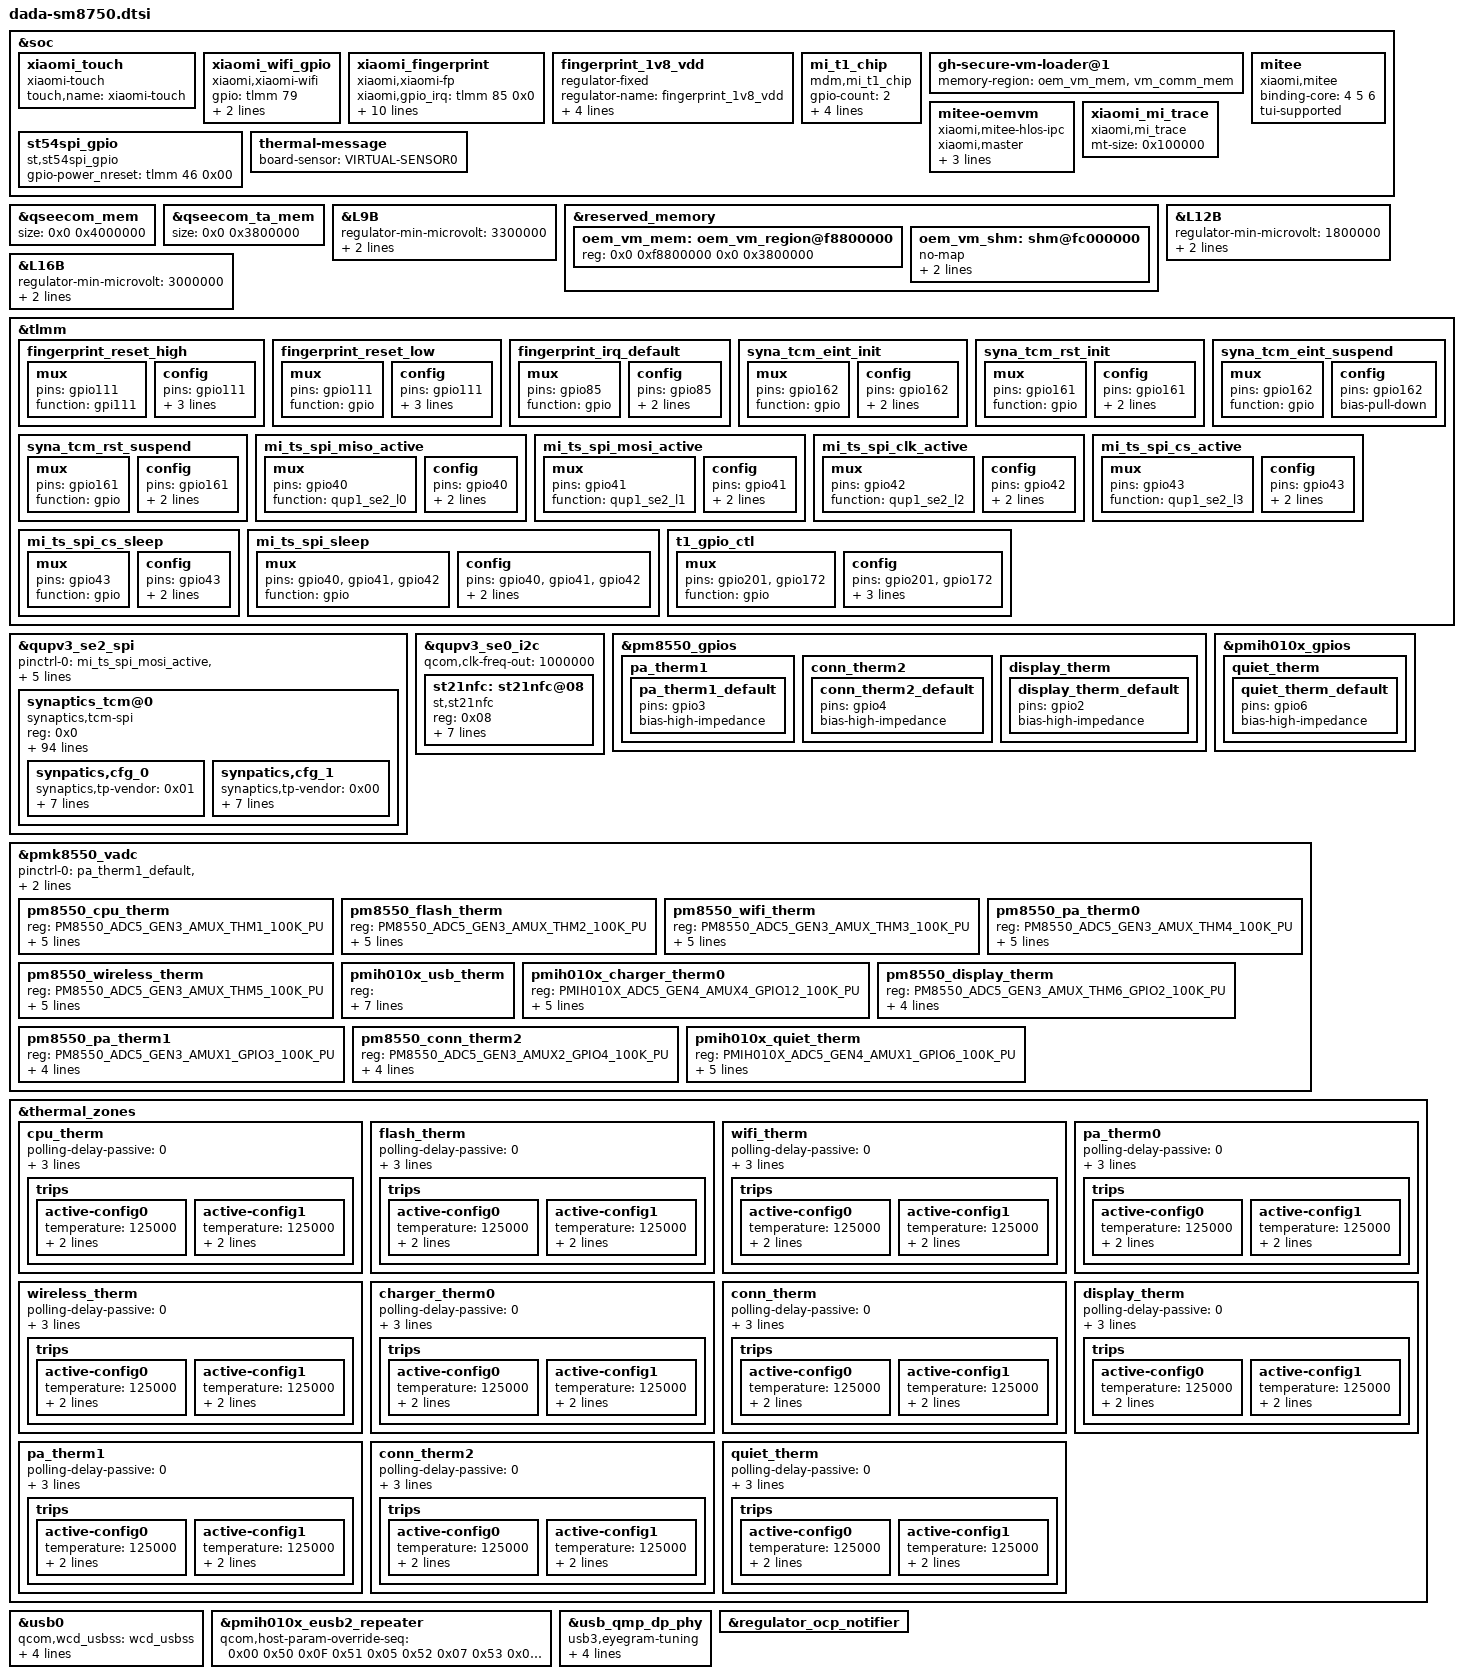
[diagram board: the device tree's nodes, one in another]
/*
  this file is for attribution only of dada
  And public attribution of xiaomi platforms(like O2 O3)
*/

#include "dada-pinctrl.dtsi"
#include "sm8750-xiaomi-common.dtsi"
#include "sm8750-ir-sensor-common.dtsi"
#include "dada-charger-common.dtsi"

&soc {
	xiaomi_touch {
		compatible = "xiaomi-touch";
		status = "ok";
		touch,name = "xiaomi-touch";
	};

	xiaomi_wifi_gpio {
		compatible = "xiaomi,xiaomi-wifi";
		gpio = <&tlmm 79 0x00>;
		debounce-time = <30>;
		pinctrl-names = "default";
		pinctrl-0 = <&wifi_ctrl_irq>;
		status = "ok";
	};

	xiaomi_fingerprint {
		compatible = "xiaomi,xiaomi-fp";
		xiaomi,gpio_irq = <&tlmm 85 0x0>;
		xiaomi,gpio_ipc = <&tlmm 85 0x0>;
		xiaomi,gpio_intr2 = <&tlmm 111 0x0>;
		xiaomi,vendor_names = "O3_n2_431_131";
		fp_3v3_vreg-supply = <&L9B>;
		fp_1v8_vreg-supply = <&fingerprint_1v8_vdd>;
		netlink-event = <25>;
		sensor-loc = <480 1906 719 2165>;
		pinctrl-names = "reset_high", "reset_low","irq_default";
		pinctrl-0 = <&fingerprint_reset_high>;
		pinctrl-1 = <&fingerprint_reset_low>;
		pinctrl-2 = <&fingerprint_irq_default>;
		status = "ok";
	};

	fingerprint_1v8_vdd: fingerprint_1v8_vdd {
		compatible = "regulator-fixed";
		regulator-name = "fingerprint_1v8_vdd";
		regulator-min-microvolt = <1800000>;
		regulator-max-microvolt = <1800000>;
		gpio = <&tlmm 76 0x0>;
		enable-active-high;
	};


	mi_t1_chip {
		compatible = "mdm,mi_t1_chip";
		gpio-count = <2>;
		first-gpio = <201>;
		mi-t1-gpio-1 = <&tlmm 201 0x0>;
		mi-t1-gpio-2 = <&tlmm 172 0x0>;
                pinctrl-0 = <&t1_gpio_ctl>;
	};
};

&qseecom_mem {
		size = <0x0 0x4000000>;
};

&qseecom_ta_mem {
		size = <0x0 0x3800000>;
};

&L9B {
	regulator-min-microvolt = <3300000>;
	regulator-max-microvolt = <3300000>;
	qcom,init-voltage = <3300000>;
};

/* mitee vm */
&reserved_memory {
	oem_vm_mem: oem_vm_region@f8800000 {
		reg = <0x0 0xf8800000 0x0 0x3800000>;
	};

	oem_vm_shm: shm@fc000000 {
		no-map;
		reg = <0x0 0xfc000000 0x0 0x400000>;
		gunyah-label = <0x3>;
	};
};

&soc {
	gh-secure-vm-loader@1 {
		memory-region = <&oem_vm_mem &vm_comm_mem>;
	};

	mitee: mitee {
		compatible = "xiaomi,mitee";
		binding-core = <4 5 6>;
		tui-supported;
	};

	mitee-oemvm {
		compatible = "xiaomi,mitee-hlos-ipc";
		xiaomi,master;
		gunyah-shm-label = <0x3>;
		peer-name = <0x4>;
		shared-buffer = <&oem_vm_shm>;
	};
};
/* mitee vm */

&L12B {
	regulator-min-microvolt = <1800000>;
	regulator-max-microvolt = <1800000>;
	qcom,init-voltage = <1800000>;
};

&L16B {
	regulator-min-microvolt = <3000000>;
	regulator-max-microvolt = <3000000>;
	qcom,init-voltage = <3000000>;
};

&tlmm {
	/* FP_RESET_HIGH, state device active*/
	fingerprint_reset_high: fingerprint_reset_high {
		mux {
			pins = "gpio111";
			function = "gpi111";
		};
		config {
			pins = "gpio111";
			drive-strength = <2>;
			bias-disable;
			output-high;
		};
	};
	/* FP_RESET_LOW */
	fingerprint_reset_low: fingerprint_reset_low {
		mux {
			pins = "gpio111";
			function = "gpio";
		};
		config {
			pins = "gpio111";
			drive-strength = <2>;
			bias-disable;
			output-low;
		};
	};
	/* FP_INT_N */
		fingerprint_irq_default: fingerprint_irq_default {
		mux {
			pins = "gpio85";
			function = "gpio";
		};
		config {
			pins = "gpio85";
			drive-strength = <2>;
			bias-pull-down;
		};
	};
	syna_tcm_eint_init: syna_tcm_eint_init {
		mux {
			/* GPIO 162 Interrupt */
			pins = "gpio162";
			function = "gpio";
		};

		config {
			pins = "gpio162";
			bias-disable;
			input-enable;
		};
	};

	syna_tcm_rst_init: syna_tcm_rst_init {
		mux {
			/* GPIO 161 Interrupt */
			pins = "gpio161";
			function = "gpio";
		};

		config {
			pins = "gpio161";
			bias-disable;
			output-low;
		};
	};

	syna_tcm_eint_suspend: syna_tcm_eint_suspend {
		mux {
			/* GPIO 162 Interrupt */
			pins = "gpio162";
			function = "gpio";
		};

		config {
			pins = "gpio162";
			bias-pull-down;
		};
	};

	syna_tcm_rst_suspend: syna_tcm_rst_suspend {
		mux {
			/* GPIO 161 Interrupt */
			pins = "gpio161";
			function = "gpio";
		};

		config {
			pins = "gpio161";
			bias-pull-down;
			output-low;
		};
	};

	mi_ts_spi_miso_active: mi_ts_spi_miso_active {
		mux {
			pins = "gpio40";
			function = "qup1_se2_l0";
		};
		config {
			pins = "gpio40";
			drive-strength = <6>;
			bias-pull-down;
		};
	};

	mi_ts_spi_mosi_active: mi_ts_spi_mosi_active {
		mux {
			pins = "gpio41";
			function = "qup1_se2_l1";
		};
		config {
			pins = "gpio41";
			drive-strength = <6>;
			bias-pull-down;
		};
	};

	mi_ts_spi_clk_active: mi_ts_spi_clk_active {
		mux {
			pins = "gpio42";
			function = "qup1_se2_l2";
		};
		config {
			pins = "gpio42";
			drive-strength = <6>;
			bias-pull-down;
		};
	};

	mi_ts_spi_cs_active: mi_ts_spi_cs_active {
		mux {
			pins = "gpio43";
			function = "qup1_se2_l3";
		};
		config {
			pins = "gpio43";
			drive-strength = <6>;
			bias-pull-down;
		};
	};


	mi_ts_spi_cs_sleep: mi_ts_spi_cs_sleep {
		mux {
			pins = "gpio43";
			function = "gpio";
		};
		config {
			pins = "gpio43";
			drive-strength = <6>;
			bias-pull-up;
		};
	};

	mi_ts_spi_sleep: mi_ts_spi_sleep {
		mux {
			pins = "gpio40", "gpio41",
				"gpio42";
			function = "gpio";
		};
		config {
			pins = "gpio40", "gpio41",
				"gpio42";
			drive-strength = <2>;
			bias-pull-down;
		};
	};
	t1_gpio_ctl: t1_gpio_ctl {
		mux {
			pins = "gpio201", "gpio172";
			function = "gpio";
		};
		config {
			pins = "gpio201", "gpio172";
			drive-strength = <2>;
			bias-disable;
			output-enable;
		};
	};
};

&qupv3_se2_spi {
	status = "ok";
	pinctrl-0 = <&mi_ts_spi_mosi_active>, <&mi_ts_spi_miso_active>,
				<&mi_ts_spi_clk_active>, <&mi_ts_spi_cs_active>;
	pinctrl-1 = <&mi_ts_spi_sleep>, <&mi_ts_spi_cs_sleep>;
	qcom,la-vm;
	qcom,rt;
	synaptics_tcm@0 {
		compatible = "synaptics,tcm-spi";
		reg = <0x0>;
		spi-max-frequency = <15000000>;
		interrupt-parent = <&tlmm>;
		interrupts = <162 0x2008>;
		synaptics,avdd-name = "avdd";
		avdd-supply = <&L16B>;
		synaptics,iovdd-name = "iovdd";
		iovdd-supply = <&L12B>;
		/*synaptics,bus-reg-name = "vdd";*/
		/*synaptics,pwr-reg-name = "avdd";*/
		synaptics,irq-gpio = <&tlmm 162 0x2008>;
		synaptics,reset-gpio = <&tlmm 161 0x00>;
		synaptics,irq-on-state = <0>;
		synaptics,spi-mode = <0>;
		synaptics,byte-delay-us = <0>;
		synaptics,block-delay-us = <0>;
		synaptics,power-delay-ms = <50>;
		synaptics,reset-active-ms = <10>;
		synaptics,reset-delay-ms = <200>;
		synaptics,ubl-max-freq = <15000000>;
		synaptics,ubl-byte-delay-us = <20>;
		synaptics,fod-lx=<500>;
		synaptics,fod-ly=<1936>;
		synaptics,fod-x-size=<199>;
		synaptics,fod-y-size=<199>;
		synaptics,max-x = <1200>;
		synaptics,max-y = <2670>;
		synaptics,rx-num = <17>;
		synaptics,tx-num = <38>;
		synaptics,special-rx-num = <17>;
		synaptics,special-tx-num = <38>;
		synaptics,frame-data-page-size = <1>;
		synaptics,frame-data-buf-size = <10>;
		synaptics,raw-data-page-size = <5>;
		synaptics,raw-data-buf-size = <5>;
		pinctrl-names = "pmx_ts_active","pmx_ts_suspend";
		pinctrl-0 = <&syna_tcm_eint_init &syna_tcm_rst_init>;
		pinctrl-1 = <&syna_tcm_eint_suspend &syna_tcm_rst_suspend>;
		synaptics,super-resolution-factor = <100>;
		mi_tp,game-mode-array =
				<1 0 0 0 0>;  /* MAX MIN DEF SET GET	*/
		mi_tp,active-mode-array =
				<1 0 0 0 0>;  /* MAX MIN DEF SET GET	*/
		mi_tp,tolerance-array =
				<4 0 2 2 2>;  /* MAX MIN DEF SET GET	*/
		mi_tp,up-threshold-array =
				<4 0 3 3 3>;  /* MAX MIN DEF SET GET	*/
		mi_tp,aim-sensitivity-array =
				<4 0 2 2 2>;  /* MAX MIN DEF SET GET	*/
		mi_tp,tap-stability-array =
				<4 0 2 2 2>;  /* MAX MIN DEF SET GET	*/
		mi_tp,edge-filter-array =
				<3 0 2 2 2>;  /* MAX MIN DEF SET GET	*/
		mi_tp,panel-orien-array =
				<3 0 0 0 0>;  /* MAX MIN DEF SET GET	*/
		mi_tp,report-rate-array =
				<3 0 0 0 0>;  /* MAX MIN DEF SET GET	*/
		mi_tp,expert-mode-array =
				<3 1 1 1 1>;  /* MAX MIN DEF SET GET	*/
		mi_tp,cornerfilter-area-step-array = <0 100 170 250>; /* step 0 to step 3 */
		mi_tp,cornerzone-filter-hor1-array =
			/* B0:Type, B1:pos, B2:x0, B3:y0, B4:x1, B5:y1, B6:reserved, B7: reserved */
				<0 0 0 0 170 170 0 0>,
				<0 1 0 0 0 0 0 0>,
				<0 2 0 2229 170 2399 0 0>,
				<0 3 0 0 0 0 0 0>;
		mi_tp,cornerzone-filter-hor2-array =
			/* B0:Type, B1:pos, B2:x0, B3:y0, B4:x1, B5:y1, B6:reserved, B7: reserved */
				<0 0 0 0 0 0 0 0>,
				<0 1 909 0 1079 170 0 0>,
				<0 2 0 0 0 0 0 0>,
				<0 3 909 2229 1079 2399 0 0>;
		mi_tp,cornerzone-filter-ver-array =
			/* B0:Type, B1:pos, B2:x0, B3:y0, B4:x1, B5:y1, B6:reserved, B7: reserved */
				<0 0 0 0 0 0 0 0>,
				<0 1 0 0 0 0 0 0>,
				<0 2 0 2099 150 2399 0 0>,
				<0 3 929 2099 1079 2399 0 0>;
		mi_tp,deadzone-filter-hor-array =
			/* B0:Type, B1:pos, B2:x0, B3:y0, B4:x1, B5:y1, B6:reserved, B7: reserved */
				<2 0 0 0 1079 5 0 0>,
				<2 1 0 2394 1079 2399 0 0>,
				<2 2 0 0 0 0 0 0>,
				<2 3 0 0 0 0 0 0>;
		mi_tp,deadzone-filter-ver-array =
			/* B0:Type, B1:pos, B2:x0, B3:y0, B4:x1, B5:y1, B6:reserved, B7: reserved */
				<2 0 0 0 0 0 0 0>,
				<2 1 0 0 0 0 0 0>,
				<2 2 0 0 5 2399 0 0>,
				<2 3 1074 0 1079 2399 0 0>;
		mi_tp,edgezone-filter-hor-array =
			/* B0:Type, B1:pos, B2:x0, B3:y0, B4:x1, B5:y1, B6:reserved, B7: reserved */
				<1 0 0 0 1079 40 0 0>,
				<1 1 0 2359 1079 2399 0 0>,
				<1 2 0 0 40 2399 0 0>,
				<1 3 1039 0 1079 2399 0 0>;
		mi_tp,edgezone-filter-ver-array =
			/* B0:Type, B1:pos, B2:x0, B3:y0, B4:x1, B5:y1, B6:reserved, B7: reserved */
				<1 0 0 0 0 0 0 0>,
				<1 1 0 0 0 0 0 0>,
				<1 2 0 0 40 2399 0 0>,
				<1 3 1039 0 1079 2399 0 0>;
		synaptics,panel-display-resolution = <1440 3200>;  /* X  Y*/
		syna,qts_en;
		syna,touch-type = "primary";
		qts,trusted-touch-mode = "vm_mode";
		qts,touch-environment = "tvm";
		qts,trusted-touch-type = "primary";
		qts,trusted-touch-spi-irq = <652>;
		qts,trusted-touch-io-bases = <0xa88000>;
		qts,trusted-touch-io-sizes = <0x1000>;
		qts,trusted-touch-vm-gpio-list = <&tlmm 40 0 &tlmm 41 0 &tlmm 42 0
                                          &tlmm 43 0 &tlmm 161 0 &tlmm 162 0x2008>;
		synaptics,config-array-size = <2>;
		synaptics,default-thp-config-name = "dada_syna_thp_config.ini";
		synaptics,default-fw-image-name = "synaptics_spi_dada_00.img";
		synaptics,default-test-limit-name = "dada_test_limits_S3910P.csv";
		synpatics,cfg_0 {
			synaptics,tp-vendor = <0x01>;
			synaptics,dp-vendor = <0x42>;
			synaptics,thp-config-name = "dada_syna_thp_config.ini";
			synaptics,fw-image-name = "synaptics_spi_dada_00.img";
			synaptics,test-limit-name = "dada_test_limits_S3910P.csv";
		};
		synpatics,cfg_1 {
			synaptics,tp-vendor = <0x00>;
			synaptics,dp-vendor = <0x45>;
			synaptics,thp-config-name = "dada_syna_thp_config.ini";
			synaptics,fw-image-name = "synaptics_spi_dada_01.img";
			synaptics,test-limit-name = "dada_test_limits_S3910P.csv";
		};
	};
};

&soc {
	st54spi_gpio {
		status = "ok";
		compatible = "st,st54spi_gpio";
		/* gpio used as SE_nRESET */
		gpio-power_nreset = <&tlmm 46 0x00>;
	};
};

&qupv3_se0_i2c {
		status = "ok";
		qcom,clk-freq-out = <1000000>;
		#address-cells = <1>;
		#size-cells = <0>;
		st21nfc: st21nfc@08 {
			compatible = "st,st21nfc";
			reg = <0x08>;
			irq-gpios = <&tlmm 75 0x00>;
			reset-gpios = <&tlmm 34 0x00>;
			clkreq-gpios = <&tlmm 35 0x00>;
			interrupt-parent = <&tlmm>;
			interrupts = <75 0>;
			interrupt-names = "nfc_irq";
			pinctrl-names = "nfc_active", "nfc_suspend";
			pinctrl-0 = <&nfc_int_active &nfc_enable_active>;
			pinctrl-1 = <&nfc_int_suspend &nfc_enable_suspend>;
		};
};

&pm8550_gpios {
	pa_therm1 {
		pa_therm1_default: pa_therm1_default {
		pins = "gpio3";
		bias-high-impedance;
		};
	};
};

&pm8550_gpios {
	conn_therm2 {
		conn_therm2_default: conn_therm2_default {
		pins = "gpio4";
		bias-high-impedance;
		};
	};
};

&pm8550_gpios {
        display_therm {
                display_therm_default: display_therm_default {
                pins = "gpio2";
                bias-high-impedance;
                };
        };
};

&pmih010x_gpios {
	quiet_therm {
		quiet_therm_default: quiet_therm_default {
		pins = "gpio6";
		bias-high-impedance;
		};
	};
};

&pmk8550_vadc {

	pinctrl-names = "default";
	pinctrl-0 =<&pa_therm1_default>,<&conn_therm2_default>,<&quiet_therm_default>,<&display_therm_default>;

	pm8550_cpu_therm {
		reg = <PM8550_ADC5_GEN3_AMUX_THM1_100K_PU>;
		label = "pm8550_cpu_therm";
		qcom,ratiometric;
		qcom,hw-settle-time = <200>;
		qcom,pre-scaling = <1 1>;
		qcom,adc-tm-type = <1>;
	};

	pm8550_flash_therm {
		reg = <PM8550_ADC5_GEN3_AMUX_THM2_100K_PU>;
		label = "pm8550_flash_therm";
		qcom,ratiometric;
		qcom,hw-settle-time = <200>;
		qcom,pre-scaling = <1 1>;
		qcom,adc-tm-type = <1>;
	};

	pm8550_wifi_therm {
		reg = <PM8550_ADC5_GEN3_AMUX_THM3_100K_PU>;
		label = "pm8550_wifi_therm";
		qcom,ratiometric;
		qcom,hw-settle-time = <200>;
		qcom,pre-scaling = <1 1>;
		qcom,adc-tm-type = <1>;
	};

	pm8550_pa_therm0 {
		reg = <PM8550_ADC5_GEN3_AMUX_THM4_100K_PU>;
		label = "pm8550_pa_therm0";
		qcom,ratiometric;
		qcom,hw-settle-time = <200>;
		qcom,pre-scaling = <1 1>;
		qcom,adc-tm-type = <1>;
	};

	pm8550_wireless_therm {
		reg = <PM8550_ADC5_GEN3_AMUX_THM5_100K_PU>;
		label = "pm8550_wireless_therm";
		qcom,ratiometric;
		qcom,hw-settle-time = <200>;
		qcom,pre-scaling = <1 1>;
		qcom,adc-tm-type = <1>;
	};

	pmih010x_usb_therm {
		reg = <PMIH010X_ADC5_GEN4_AMUX_THM4_USB_THERM_100K_PU>;
		label = "pmih010x_usb_therm";
		qcom,ratiometric;
		qcom,hw-settle-time = <200>;
		qcom,pre-scaling = <1 1>;
		qcom,adc-tm-type = <1>;
		qcom,adc5-gen4;
	};

	pmih010x_charger_therm0 {
		reg = <PMIH010X_ADC5_GEN4_AMUX4_GPIO12_100K_PU>;
		label = "pmih010x_charger_therm0";
		qcom,ratiometric;
		qcom,pre-scaling = <1 1>;
		qcom,adc-tm-type = <1>;
		qcom,adc5-gen4;
	};

	pm8550_display_therm {
		reg = <PM8550_ADC5_GEN3_AMUX_THM6_GPIO2_100K_PU>;
		label = "pm8550_display_therm";
		qcom,ratiometric;
		qcom,pre-scaling = <1 1>;
		qcom,adc-tm-type = <1>;
	};

	pm8550_pa_therm1 {
		reg = <PM8550_ADC5_GEN3_AMUX1_GPIO3_100K_PU>;
		label = "pm8550_pa_therm1";
		qcom,ratiometric;
		qcom,pre-scaling = <1 1>;
		qcom,adc-tm-type = <1>;
	};

	pm8550_conn_therm2 {
		reg = <PM8550_ADC5_GEN3_AMUX2_GPIO4_100K_PU>;
		label = "pm8550_conn_therm2";
		qcom,ratiometric;
		qcom,pre-scaling = <1 1>;
		qcom,adc-tm-type = <1>;
	};

	pmih010x_quiet_therm {
		reg = <PMIH010X_ADC5_GEN4_AMUX1_GPIO6_100K_PU>;
		label = "pmih010x_quiet_therm";
		qcom,ratiometric;
		qcom,pre-scaling = <1 1>;
		qcom,adc-tm-type = <1>;
        qcom,adc5-gen4;
	};

};

&thermal_zones {
	cpu_therm {
		polling-delay-passive = <0>;
		polling-delay = <0>;
		thermal-sensors = <&pmk8550_vadc PM8550_ADC5_GEN3_AMUX_THM1_100K_PU>;
		trips {
			active-config0 {
				temperature = <125000>;
				hysteresis = <1000>;
				type = "passive";
			};

			active-config1 {
				temperature = <125000>;
				hysteresis = <1000>;
				type = "passive";
			};
		};
	};

	flash_therm {
		polling-delay-passive = <0>;
		polling-delay = <0>;
		thermal-sensors = <&pmk8550_vadc PM8550_ADC5_GEN3_AMUX_THM2_100K_PU>;
		trips {
			active-config0 {
				temperature = <125000>;
				hysteresis = <1000>;
				type = "passive";
			};

			active-config1 {
				temperature = <125000>;
				hysteresis = <1000>;
				type = "passive";
			};
		};
	};

	wifi_therm {
		polling-delay-passive = <0>;
		polling-delay = <0>;
		thermal-sensors = <&pmk8550_vadc PM8550_ADC5_GEN3_AMUX_THM3_100K_PU>;
		trips {
			active-config0 {
				temperature = <125000>;
				hysteresis = <1000>;
				type = "passive";
			};

			active-config1 {
				temperature = <125000>;
				hysteresis = <1000>;
				type = "passive";
			};
		};
	};

	pa_therm0 {
		polling-delay-passive = <0>;
		polling-delay = <0>;
		thermal-sensors = <&pmk8550_vadc PM8550_ADC5_GEN3_AMUX_THM4_100K_PU>;
		trips {
			active-config0 {
				temperature = <125000>;
				hysteresis = <1000>;
				type = "passive";
			};

			active-config1 {
				temperature = <125000>;
				hysteresis = <1000>;
				type = "passive";
			};
		};
	};

	wireless_therm {
		polling-delay-passive = <0>;
		polling-delay = <0>;
		thermal-sensors = <&pmk8550_vadc PM8550_ADC5_GEN3_AMUX_THM5_100K_PU>;
		trips {
			active-config0 {
				temperature = <125000>;
				hysteresis = <1000>;
				type = "passive";
			};

			active-config1 {
				temperature = <125000>;
				hysteresis = <1000>;
				type = "passive";
			};
		};
	};

	charger_therm0 {
		polling-delay-passive = <0>;
		polling-delay = <0>;
		thermal-sensors = <&pmk8550_vadc PMIH010X_ADC5_GEN4_AMUX4_GPIO12_100K_PU>;
		trips {
			active-config0 {
				temperature = <125000>;
				hysteresis = <1000>;
				type = "passive";
			};

			active-config1 {
				temperature = <125000>;
				hysteresis = <1000>;
				type = "passive";
			};
		};
	};

	conn_therm {
		polling-delay-passive = <0>;
		polling-delay = <0>;
		thermal-sensors = <&pmk8550_vadc PMIH010X_ADC5_GEN4_AMUX_THM4_USB_THERM_100K_PU>;
		trips {
			active-config0 {
				temperature = <125000>;
				hysteresis = <1000>;
				type = "passive";
			};

			active-config1 {
				temperature = <125000>;
				hysteresis = <1000>;
				type = "passive";
			};
		};
	};

	display_therm {
		polling-delay-passive = <0>;
		polling-delay = <0>;
		thermal-sensors = <&pmk8550_vadc PM8550_ADC5_GEN3_AMUX_THM6_GPIO2_100K_PU>;
		trips {
			active-config0 {
				temperature = <125000>;
				hysteresis = <1000>;
				type = "passive";
			};

			active-config1 {
				temperature = <125000>;
				hysteresis = <1000>;
				type = "passive";
			};
		};
	};

	pa_therm1 {
		polling-delay-passive = <0>;
		polling-delay = <0>;
		thermal-sensors = <&pmk8550_vadc PM8550_ADC5_GEN3_AMUX1_GPIO3_100K_PU>;
		trips {
			active-config0 {
				temperature = <125000>;
				hysteresis = <1000>;
				type = "passive";
			};

			active-config1 {
				temperature = <125000>;
				hysteresis = <1000>;
				type = "passive";
			};
		};
	};

	conn_therm2 {
		polling-delay-passive = <0>;
		polling-delay = <0>;
		thermal-sensors = <&pmk8550_vadc PM8550_ADC5_GEN3_AMUX2_GPIO4_100K_PU>;
		trips {
			active-config0 {
				temperature = <125000>;
				hysteresis = <1000>;
				type = "passive";
			};

			active-config1 {
				temperature = <125000>;
				hysteresis = <1000>;
				type = "passive";
			};
		};
	};

	quiet_therm {
		polling-delay-passive = <0>;
		polling-delay = <0>;
		thermal-sensors = <&pmk8550_vadc PMIH010X_ADC5_GEN4_AMUX1_GPIO6_100K_PU>;
		trips {
			active-config0 {
				temperature = <125000>;
				hysteresis = <1000>;
				type = "passive";
			};

			active-config1 {
				temperature = <125000>;
				hysteresis = <1000>;
				type = "passive";
			};
		};
	};
};

&soc {
 	thermal-message {
  		board-sensor = "VIRTUAL-SENSOR0";
 	};
 };

&usb0 {
	qcom,wcd_usbss = <&wcd_usbss>;
	wcd_equ = <0xC0>;
	wcd_equ_host = <0xC0>;
	maximum_speed = "super-speed";
	host-force-gen1;
};
&pmih010x_eusb2_repeater {
        qcom,host-param-override-seq =
                <0x00 0x50
                0x0F 0x51
                0x05 0x52
                0x07 0x53
                0x03 0x54
                0x03 0x55
                0x00 0x56
                0x03 0x57
                0x02 0x58
                0x03 0x59
                0x01 0x5a
                0x02 0x5b>;
};
&usb_qmp_dp_phy {
	usb3,eyegram-tuning;
	qcom,usb3-phy-eye-seq =
	/* <reg_offset, value>*/
		<USB3_DP_PCS_G12S1_TXMGN_V0 0x1F
			USB3_DP_PCS_G12S1_TXDEEMPH_M3P5DB 0x18>;
	qcom,host-usb3-phy-eye-seq =
		<USB3_DP_PCS_G12S1_TXMGN_V0 0x1F
			USB3_DP_PCS_G12S1_TXDEEMPH_M3P5DB 0x17>;
};

/*Remove PM8010 N for hardware design*/
&regulator_ocp_notifier {
	/delete-property/ periph-d40-supply;
	/delete-property/ periph-d41-supply;
	/delete-property/ periph-d42-supply;
	/delete-property/ periph-d43-supply;
	/delete-property/ periph-d44-supply;
	/delete-property/ periph-d45-supply;
	/delete-property/ periph-d46-supply;
};

&soc {
	xiaomi_mi_trace{
		compatible = "xiaomi,mi_trace";
		mt-size = <0x100000>;
	};
};
